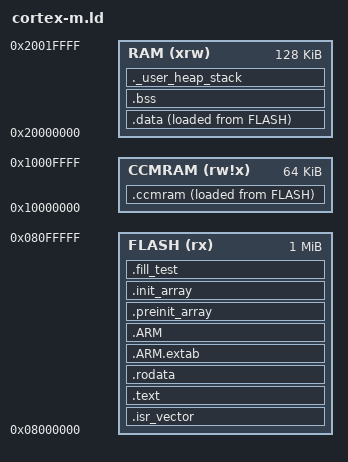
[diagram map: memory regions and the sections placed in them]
/* A Cortex-M bare-metal script in the style of vendor SDK templates,
   written for qld's tests. */
ENTRY(Reset_Handler)

_estack = ORIGIN(RAM) + LENGTH(RAM);
_Min_Heap_Size = 0x200;
_Min_Stack_Size = 0x400;

MEMORY
{
  FLASH (rx)      : ORIGIN = 0x08000000, LENGTH = 1024K
  RAM (xrw)       : ORIGIN = 0x20000000, LENGTH = 128K
  CCMRAM (rw!x)   : org = 0x10000000, len = 64K
}

REGION_ALIAS("REGION_TEXT", FLASH);

SECTIONS
{
  .isr_vector :
  {
    . = ALIGN(4);
    KEEP(*(.isr_vector))
    . = ALIGN(4);
  } >FLASH

  .text :
  {
    . = ALIGN(4);
    *(.text)
    *(.text*)
    *(.glue_7)
    *(.glue_7t)
    *(.eh_frame)
    KEEP (*(.init))
    KEEP (*(.fini))
    . = ALIGN(4);
    _etext = .;
  } >REGION_TEXT

  .rodata :
  {
    . = ALIGN(4);
    *(.rodata)
    *(.rodata*)
    . = ALIGN(4);
  } >FLASH

  .ARM.extab : { *(.ARM.extab* .gnu.linkonce.armextab.*) } >FLASH
  .ARM : {
    __exidx_start = .;
    *(.ARM.exidx*)
    __exidx_end = .;
  } >FLASH

  .preinit_array :
  {
    PROVIDE_HIDDEN (__preinit_array_start = .);
    KEEP (*(.preinit_array*))
    PROVIDE_HIDDEN (__preinit_array_end = .);
  } >FLASH

  .init_array :
  {
    PROVIDE_HIDDEN (__init_array_start = .);
    KEEP (*(SORT(.init_array.*)))
    KEEP (*(.init_array*))
    PROVIDE_HIDDEN (__init_array_end = .);
  } >FLASH

  _sidata = LOADADDR(.data);

  .data :
  {
    . = ALIGN(4);
    _sdata = .;
    *(.data)
    *(.data*)
    . = ALIGN(4);
    _edata = .;
  } >RAM AT> FLASH

  .ccmram : { *(.ccmram .ccmram*) } >CCMRAM AT> FLASH

  . = ALIGN(4);
  .bss :
  {
    _sbss = .;
    __bss_start__ = _sbss;
    *(.bss)
    *(.bss*)
    *(COMMON)
    . = ALIGN(4);
    _ebss = .;
    __bss_end__ = _ebss;
  } >RAM

  ._user_heap_stack :
  {
    . = ALIGN(8);
    PROVIDE ( end = . );
    PROVIDE ( _end = . );
    . = . + _Min_Heap_Size;
    . = . + _Min_Stack_Size;
    . = ALIGN(8);
  } >RAM

  .fill_test : { BYTE(0x11) SHORT(0x2233) LONG(0x44556677) QUAD(-1) FILL(0x9090) . += 4; } >FLASH =0xff

  /DISCARD/ :
  {
    *libc.a:* ( * )
    libm.a:* ( * )
    EXCLUDE_FILE(*crt0.o) *libgcc.a:*.o ( * )
  }

  .ARM.attributes 0 : { *(.ARM.attributes) }
}
